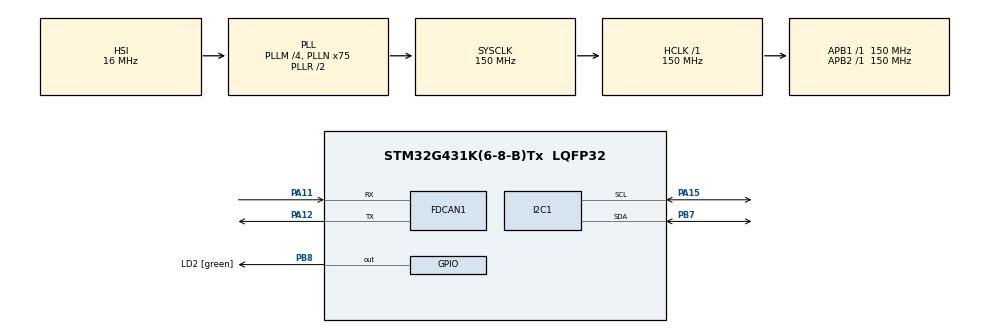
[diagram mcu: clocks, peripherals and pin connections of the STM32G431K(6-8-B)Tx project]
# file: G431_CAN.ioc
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FDCAN1.CalculateBaudRateNominal=1874999
FDCAN1.CalculateTimeBitNominal=533
FDCAN1.CalculateTimeQuantumNominal=106.66666666666667
I2C1.Timing=0x00506682
Mcu.Family=STM32G4
Mcu.Name=STM32G431K(6-8-B)Tx
Mcu.Package=LQFP32
NVIC.PriorityGroup=NVIC_PRIORITYGROUP_4
PA11.GPIO_PuPd=GPIO_PULLUP
PA11.Mode=FDCAN_Activate
PA11.Signal=FDCAN1_RX
PA12.Mode=FDCAN_Activate
PA12.Signal=FDCAN1_TX
PA13.GPIO_Label=T_SWDIO
PA13.Signal=SYS_JTMS-SWDIO
PA14.GPIO_Label=T_SWCLK
PA14.Signal=SYS_JTCK-SWCLK
PA15.Mode=I2C
PA15.Signal=I2C1_SCL
PA2.GPIO_Label=USART2_TX [ST-LINKV3E_VCP_RX]
PA2.Signal=USART2_TX
PA3.GPIO_Label=USART2_RX [ST-LINKV3E_VCP_TX]
PA3.Signal=USART2_RX
PB3.GPIO_Label=T_SWO
PB3.Signal=SYS_JTDO-SWO
PB7.Mode=I2C
PB7.Signal=I2C1_SDA
PB8-BOOT0.GPIO_Label=LD2 [green]
PB8-BOOT0.Signal=GPIO_Output
ProjectManager.HeapSize=0x200
ProjectManager.StackSize=0x400
ProjectManager.TargetToolchain=MDK-ARM V5.32
RCC.ADC12Freq_Value=150000000
RCC.AHBFreq_Value=150000000
RCC.APB1Freq_Value=150000000
RCC.APB1TimFreq_Value=150000000
RCC.APB2Freq_Value=150000000
RCC.APB2TimFreq_Value=150000000
RCC.CortexFreq_Value=150000000
RCC.EXTERNAL_CLOCK_VALUE=12288000
RCC.HCLKFreq_Value=150000000
RCC.HSE_VALUE=8000000
RCC.HSI48_VALUE=48000000
RCC.HSI_VALUE=16000000
RCC.LSE_VALUE=32768
RCC.PLLM=RCC_PLLM_DIV4
RCC.PLLN=75
RCC.SYSCLKFreq_VALUE=150000000
RCC.SYSCLKSource=RCC_SYSCLKSOURCE_PLLCLK
RCC.USBFreq_Value=150000000
RCC.VCOOutputFreq_Value=300000000
board=NUCLEO-G431KB

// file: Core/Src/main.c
/* USER CODE BEGIN Header */
/**
  ******************************************************************************
  * @file           : main.c
  * @brief          : Main program body
  ******************************************************************************
  * @attention
  *
  * Copyright (c) 2023 STMicroelectronics.
  * All rights reserved.
  *
  * This software is licensed under terms that can be found in the LICENSE file
  * in the root directory of this software component.
  * If no LICENSE file comes with this software, it is provided AS-IS.
  *
  ******************************************************************************
  */
/* USER CODE END Header */
#include "main.h"
#include "fdcan.h"
#include "i2c.h"
#include "gpio.h"

/* USER CODE BEGIN Includes */
#include "system.h"
/* USER CODE END Includes */

void SystemClock_Config(void);

int main(void)
{

  /* MCU Configuration--------------------------------------------------------*/

  /* Reset of all peripherals, Initializes the Flash interface and the Systick. */
  HAL_Init();

  /* Configure the system clock */
  SystemClock_Config();

  /* Initialize all configured peripherals */
  MX_GPIO_Init();
  MX_FDCAN1_Init();
  MX_I2C1_Init();
  /* USER CODE BEGIN 2 */
  systemInit();
	firstMessageSend();
/* USER CODE END 2 */

  /* Infinite loop */
  while (1)
  {

    /* USER CODE BEGIN 3 */
    systemProc();
  }
  /* USER CODE END 3 */
}

void SystemClock_Config(void)
{
  RCC_OscInitTypeDef RCC_OscInitStruct = {0};
  RCC_ClkInitTypeDef RCC_ClkInitStruct = {0};

  /** Configure the main internal regulator output voltage
  */
  HAL_PWREx_ControlVoltageScaling(PWR_REGULATOR_VOLTAGE_SCALE1);

  /** Initializes the RCC Oscillators according to the specified parameters
  * in the RCC_OscInitTypeDef structure.
  */
  RCC_OscInitStruct.OscillatorType = RCC_OSCILLATORTYPE_HSI;
  RCC_OscInitStruct.HSIState = RCC_HSI_ON;
  RCC_OscInitStruct.HSICalibrationValue = RCC_HSICALIBRATION_DEFAULT;
  RCC_OscInitStruct.PLL.PLLState = RCC_PLL_ON;
  RCC_OscInitStruct.PLL.PLLSource = RCC_PLLSOURCE_HSI;
  RCC_OscInitStruct.PLL.PLLM = RCC_PLLM_DIV4;
  RCC_OscInitStruct.PLL.PLLN = 75;
  RCC_OscInitStruct.PLL.PLLP = RCC_PLLP_DIV2;
  RCC_OscInitStruct.PLL.PLLQ = RCC_PLLQ_DIV2;
  RCC_OscInitStruct.PLL.PLLR = RCC_PLLR_DIV2;
  if (HAL_RCC_OscConfig(&RCC_OscInitStruct) != HAL_OK)
  {
    Error_Handler();
  }

  /** Initializes the CPU, AHB and APB buses clocks
  */
  RCC_ClkInitStruct.ClockType = RCC_CLOCKTYPE_HCLK|RCC_CLOCKTYPE_SYSCLK
                              |RCC_CLOCKTYPE_PCLK1|RCC_CLOCKTYPE_PCLK2;
  RCC_ClkInitStruct.SYSCLKSource = RCC_SYSCLKSOURCE_PLLCLK;
  RCC_ClkInitStruct.AHBCLKDivider = RCC_SYSCLK_DIV1;
  RCC_ClkInitStruct.APB1CLKDivider = RCC_HCLK_DIV1;
  RCC_ClkInitStruct.APB2CLKDivider = RCC_HCLK_DIV1;

  if (HAL_RCC_ClockConfig(&RCC_ClkInitStruct, FLASH_LATENCY_4) != HAL_OK)
  {
    Error_Handler();
  }
}

void Error_Handler(void)
{
  __disable_irq();
  while (1)
  {
  }
}
